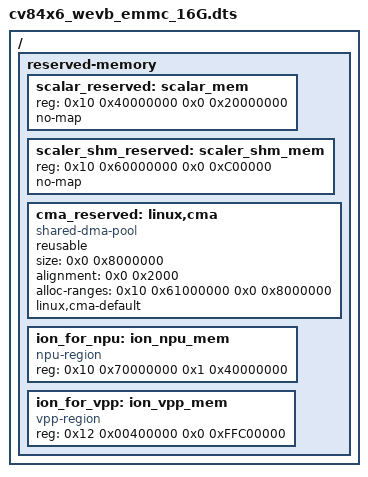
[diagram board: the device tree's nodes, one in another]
/dts-v1/;
#include "soph_base_arm64.dtsi"
#include "soph_asic_emmc.dtsi"
#include "soph_default_memmap_16G.dtsi"
#include "cv84x6_wevb_emmc.dtsi"

/ {
	reserved-memory {
		#address-cells = <0x2>;
		#size-cells = <0x2>;
		ranges;

#ifndef __UBOOT__
		scalar_reserved: scalar_mem {
			reg = <0x10 0x40000000 0x0 0x20000000>;	//512MB for TPU firmware
			no-map;
		};
		scaler_shm_reserved: scaler_shm_mem {
			reg = <0x10 0x60000000 0x0 0xC00000>;	//12MB after scalar parks
			no-map;
		};

		cma_reserved: linux,cma {
			compatible = "shared-dma-pool";
			reusable;
			size = <0x0 0x8000000>; // 128MB
			alignment = <0x0 0x2000>; // 8KB
			alloc-ranges = <0x10 0x61000000 0x0 0x8000000>;
			linux,cma-default;
		};
		ion_for_npu: ion_npu_mem {
			compatible = "npu-region";
			reg = <0x10 0x70000000 0x1 0x40000000>; // 5GB for TPU
		};

		ion_for_vpp: ion_vpp_mem {
			compatible = "vpp-region";
			reg = <0x12 0x00400000 0x0 0xFFC00000>; // ~4GB for VPP
		};
#endif
	};
};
